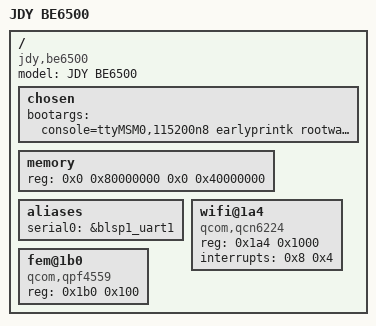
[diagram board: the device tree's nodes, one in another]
// SPDX-License-Identifier: GPL-2.0
#include <dt-bindings/clock/qcom,gcc-ipq5018.h>
#include "ipq5018.dtsi"

/ {
    model = "JDY BE6500";
    compatible = "jdy,be6500", "qcom,ipq5018";

    chosen {
        bootargs = "console=ttyMSM0,115200n8 earlyprintk rootwait";
    };

    memory {
        device_type = "memory";
        reg = <0x0 0x80000000 0x0 0x40000000>; /* 1GB RAM */
    };

    aliases {
        serial0 = &blsp1_uart1;
    };

    wifi@1a4 {
        compatible = "qcom,qcn6224";
        reg = <0x1a4 0x1000>;
        interrupts = <0x8 0x4>;
        interrupt-names = "wlan_irq";
        status = "okay";
    };

    fem@1b0 {
        compatible = "qcom,qpf4559";
        reg = <0x1b0 0x100>;
        status = "okay";
    };
};
